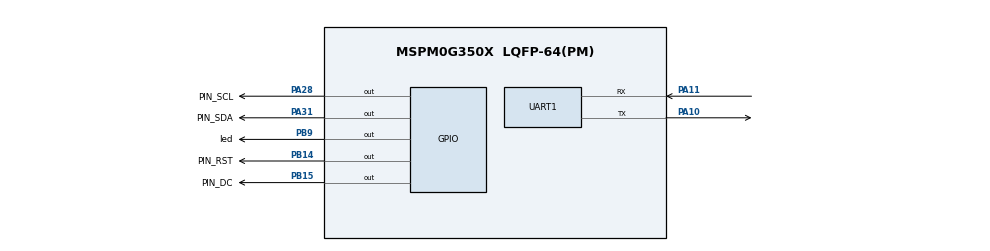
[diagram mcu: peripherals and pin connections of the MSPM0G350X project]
/**
 * @cliArgs --device "MSPM0G350X" --package "LQFP-64(PM)" --part "Default" --product "mspm0_sdk@2.01.00.03"
 * @versions {"tool":"1.20.0+3587"}
 */

/**
 * Import the modules used in this configuration.
 */
const ADC12   = scripting.addModule("/ti/driverlib/ADC12", {}, false);
const ADC121  = ADC12.addInstance();
const GPIO    = scripting.addModule("/ti/driverlib/GPIO", {}, false);
const GPIO1   = GPIO.addInstance();
const GPIO2   = GPIO.addInstance();
const GPIO3   = GPIO.addInstance();
const GPIO4   = GPIO.addInstance();
const GPIO5   = GPIO.addInstance();
const SYSCTL  = scripting.addModule("/ti/driverlib/SYSCTL");
const SYSTICK = scripting.addModule("/ti/driverlib/SYSTICK");
const UART    = scripting.addModule("/ti/driverlib/UART", {}, false);
const UART1   = UART.addInstance();

/**
 * Write custom configuration values to the imported modules.
 */
const divider7       = system.clockTree["PLL_PDIV"];
divider7.divideValue = 2;

const divider9       = system.clockTree["UDIV"];
divider9.divideValue = 2;

const multiplier2         = system.clockTree["PLL_QDIV"];
multiplier2.multiplyValue = 5;

const mux8       = system.clockTree["HSCLKMUX"];
mux8.inputSelect = "HSCLKMUX_SYSPLL2X";

ADC121.$name                      = "ADC12_0";
ADC121.sampClkSrc                 = "DL_ADC12_CLOCK_ULPCLK";
ADC121.sampClkDiv                 = "DL_ADC12_CLOCK_DIVIDE_8";
ADC121.sampleTime0                = "40 us";
ADC121.powerDownMode              = "DL_ADC12_POWER_DOWN_MODE_MANUAL";
ADC121.peripheral.$assign         = "ADC0";
ADC121.peripheral.adcPin0.$assign = "PA27";
ADC121.adcPin0Config.$name        = "ti_driverlib_gpio_GPIOPinGeneric4";

const Board = scripting.addModule("/ti/driverlib/Board", {}, false);

GPIO1.$name                         = "OLED_RST";
GPIO1.associatedPins[0].$name       = "PIN_RST";
GPIO1.associatedPins[0].pin.$assign = "PB14";

GPIO2.$name                         = "OLED_DC";
GPIO2.associatedPins[0].$name       = "PIN_DC";
GPIO2.associatedPins[0].pin.$assign = "PB15";

GPIO3.$name                         = "OLED_SCL";
GPIO3.associatedPins[0].$name       = "PIN_SCL";
GPIO3.associatedPins[0].pin.$assign = "PA28";

GPIO4.$name                         = "OLED_SDA";
GPIO4.associatedPins[0].$name       = "PIN_SDA";
GPIO4.associatedPins[0].pin.$assign = "PA31";

GPIO5.$name                         = "LED";
GPIO5.associatedPins[0].$name       = "led";
GPIO5.associatedPins[0].pin.$assign = "PB9";

SYSCTL.forceDefaultClkConfig = true;
SYSCTL.clockTreeEn           = true;

SYSTICK.periodEnable  = true;
SYSTICK.systickEnable = true;
SYSTICK.period        = 16777216;

UART1.$name                    = "UART_0";
UART1.targetBaudRate           = 115200;
UART1.enableFIFO               = true;
UART1.rxFifoThreshold          = "DL_UART_RX_FIFO_LEVEL_ONE_ENTRY";
UART1.enableDMARX              = false;
UART1.enableDMATX              = false;
UART1.enableInternalLoopback   = false;
UART1.peripheral.rxPin.$assign = "PA11";
UART1.peripheral.txPin.$assign = "PA10";
UART1.txPinConfig.$name        = "ti_driverlib_gpio_GPIOPinGeneric2";
UART1.rxPinConfig.$name        = "ti_driverlib_gpio_GPIOPinGeneric3";

/**
 * Pinmux solution for unlocked pins/peripherals. This ensures that minor changes to the automatic solver in a future
 * version of the tool will not impact the pinmux you originally saw.  These lines can be completely deleted in order to
 * re-solve from scratch.
 */
Board.peripheral.$suggestSolution          = "DEBUGSS";
Board.peripheral.swclkPin.$suggestSolution = "PA20";
Board.peripheral.swdioPin.$suggestSolution = "PA19";
UART1.peripheral.$suggestSolution          = "UART0";
